# STM32F407ZGT7 register map
File version: 1.0
Registers are 32-bit, access not given, reset 0x0 unless marked. A register's access mark holds for its fields unless they carry their own. Offsets are from the block's base; [hi:lo] are bit positions; {n}, {i} and the like mark numbered series.

## ADC123_COMMON
Base 0x40012300
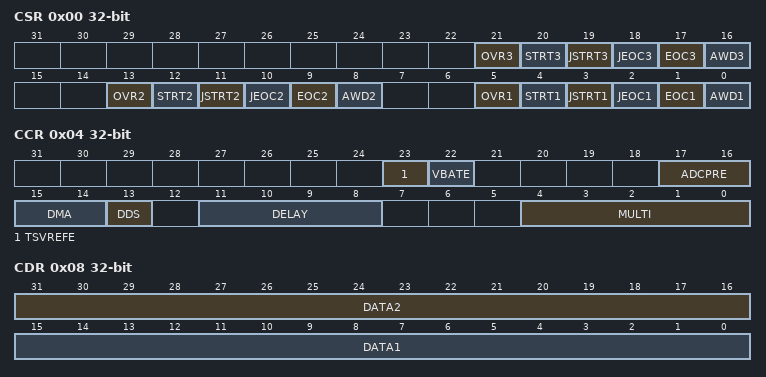
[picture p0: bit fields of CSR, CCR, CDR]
0x00 CSR
  [21] OVR3, [20] STRT3, [19] JSTRT3, [18] JEOC3, [17] EOC3, [16] AWD3, [13] OVR2, [12] STRT2, [11] JSTRT2, [10] JEOC2, [9] EOC2, [8] AWD2, [5] OVR1, [4] STRT1, [3] JSTRT1, [2] JEOC1, [1] EOC1, [0] AWD1
0x04 CCR
  [23] TSVREFE, [22] VBATE, [17:16] ADCPRE, [15:14] DMA, [13] DDS, [11:8] DELAY, [4:0] MULTI
0x08 CDR
  [31:16] DATA2, [15:0] DATA1

## SDIO
Base 0x40012C00
0x00 POWER
  [1:0] PWRCTRL
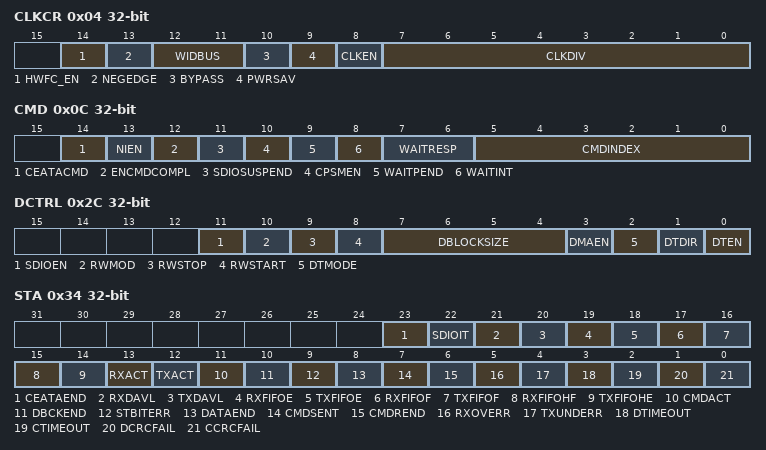
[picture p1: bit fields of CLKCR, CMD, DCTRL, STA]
0x04 CLKCR
  [14] HWFC_EN, [13] NEGEDGE, [12:11] WIDBUS, [10] BYPASS, [9] PWRSAV, [8] CLKEN, [7:0] CLKDIV
0x08 ARG
  [31:0] CMDARG
0x0C CMD
  [14] CEATACMD, [13] NIEN, [12] ENCMDCOMPL, [11] SDIOSUSPEND, [10] CPSMEN, [9] WAITPEND, [8] WAITINT, [7:6] WAITRESP, [5:0] CMDINDEX
0x10 RESPCMD
  [5:0] RESPCMD
{0x10+4i} RESP{i} (i=1..4)
  [31:0] CARDSTATUS{i}
0x24 DTIMER
  [31:0] DATATIME
0x28 DLEN
  [24:0] DATALENGTH
0x2C DCTRL
  [11] SDIOEN, [10] RWMOD, [9] RWSTOP, [8] RWSTART, [7:4] DBLOCKSIZE, [3] DMAEN, [2] DTMODE, [1] DTDIR, [0] DTEN
0x30 DCOUNT
  [24:0] DATACOUNT
0x34 STA
  [23] CEATAEND, [22] SDIOIT, [21] RXDAVL, [20] TXDAVL, [19] RXFIFOE, [18] TXFIFOE, [17] RXFIFOF, [16] TXFIFOF, [15] RXFIFOHF, [14] TXFIFOHE, [13] RXACT, [12] TXACT, [11] CMDACT, [10] DBCKEND, [9] STBITERR, [8] DATAEND, [7] CMDSENT, [6] CMDREND, [5] RXOVERR, [4] TXUNDERR, [3] DTIMEOUT, [2] CTIMEOUT, [1] DCRCFAIL, [0] CCRCFAIL
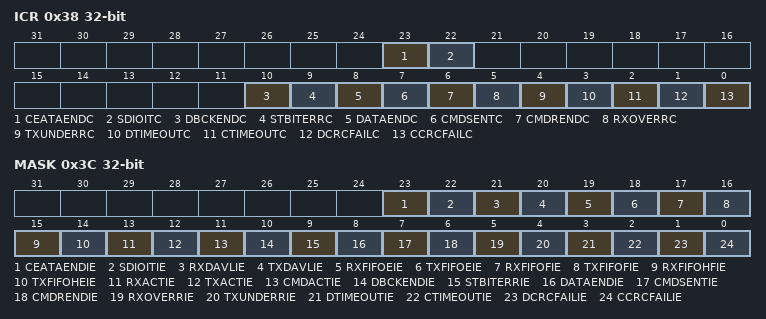
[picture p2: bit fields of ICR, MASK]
0x38 ICR
  [23] CEATAENDC, [22] SDIOITC, [10] DBCKENDC, [9] STBITERRC, [8] DATAENDC, [7] CMDSENTC, [6] CMDRENDC, [5] RXOVERRC, [4] TXUNDERRC, [3] DTIMEOUTC, [2] CTIMEOUTC, [1] DCRCFAILC, [0] CCRCFAILC
0x3C MASK
  [23] CEATAENDIE, [22] SDIOITIE, [21] RXDAVLIE, [20] TXDAVLIE, [19] RXFIFOEIE, [18] TXFIFOEIE, [17] RXFIFOFIE, [16] TXFIFOFIE, [15] RXFIFOHFIE, [14] TXFIFOHEIE, [13] RXACTIE, [12] TXACTIE, [11] CMDACTIE, [10] DBCKENDIE, [9] STBITERRIE, [8] DATAENDIE, [7] CMDSENTIE, [6] CMDRENDIE, [5] RXOVERRIE, [4] TXUNDERRIE, [3] DTIMEOUTIE, [2] CTIMEOUTIE, [1] DCRCFAILIE, [0] CCRCFAILIE
0x48 FIFOCNT
  [23:0] FIFOCOUNT
0x80 FIFO
  [31:0] FIFODATA

## SYSCFG
Base 0x40013800
0x00 MEMRMP
  [1:0] MEM_MODE
0x04 PMC
  [23] MII_RMII_SEL
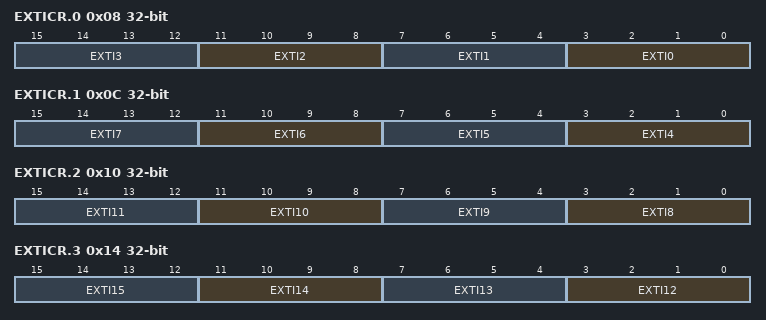
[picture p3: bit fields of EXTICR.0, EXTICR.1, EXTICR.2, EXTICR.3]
0x08 EXTICR.0
  [4n+3:4n] EXTI{n} (n=0..3)
0x0C EXTICR.1
  [4n-13:4n-16] EXTI{n} (n=4..7)
0x10 EXTICR.2
  [4n-29:4n-32] EXTI{n} (n=8..11)
0x14 EXTICR.3
  [4n-45:4n-48] EXTI{n} (n=12..15)
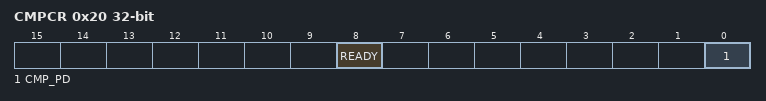
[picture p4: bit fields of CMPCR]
0x20 CMPCR
  [8] READY, [0] CMP_PD

## EXTI
Base 0x40013C00
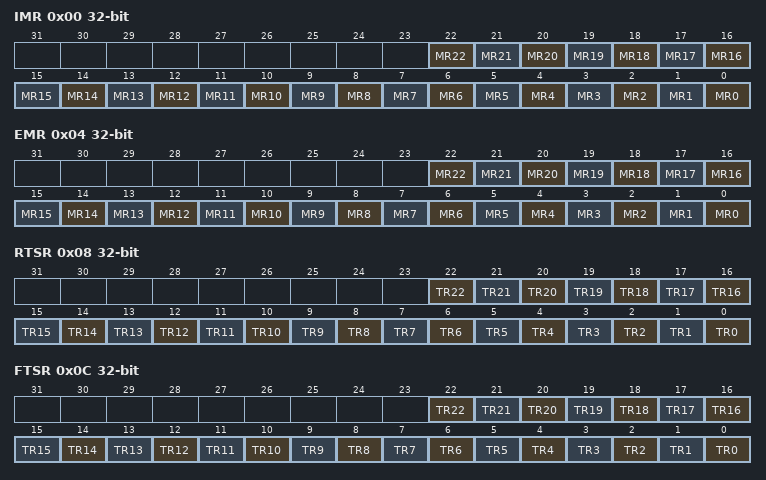
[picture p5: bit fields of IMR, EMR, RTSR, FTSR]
0x00 IMR
  [n] MR{n} (n=0..22)
0x04 EMR
  [n] MR{n} (n=0..22)
0x08 RTSR
  [n] TR{n} (n=0..22)
0x0C FTSR
  [n] TR{n} (n=0..22)
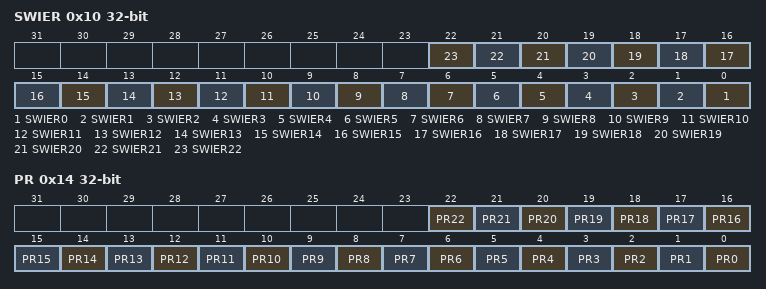
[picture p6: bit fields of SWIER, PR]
0x10 SWIER
  [n] SWIER{n} (n=0..22)
0x14 PR
  [n] PR{n} (n=0..22)

## GPIOA
Base 0x40020000
Same registers: GPIOB 0x40020400, GPIOC 0x40020800, GPIOD 0x40020C00, GPIOE 0x40021000, GPIOF 0x40021400, GPIOG 0x40021800, GPIOH 0x40021C00, GPIOI 0x40022000
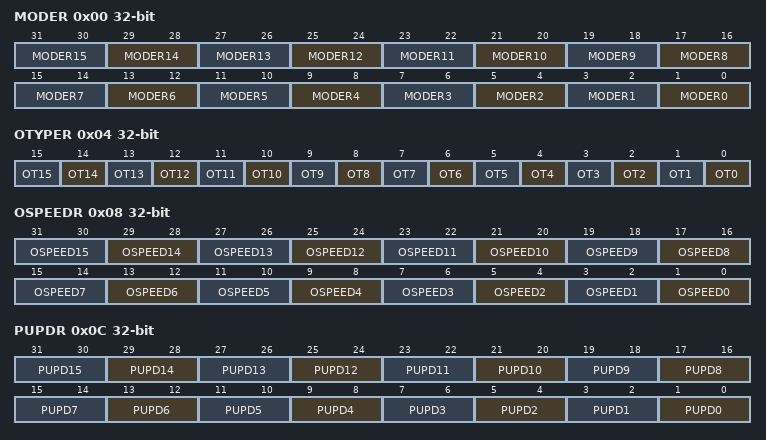
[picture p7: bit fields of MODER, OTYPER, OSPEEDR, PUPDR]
0x00 MODER
  [2n+1:2n] MODER{n} (n=0..15)
0x04 OTYPER
  [n] OT{n} (n=0..15)
0x08 OSPEEDR
  [2n+1:2n] OSPEED{n} (n=0..15)
0x0C PUPDR
  [2n+1:2n] PUPD{n} (n=0..15)
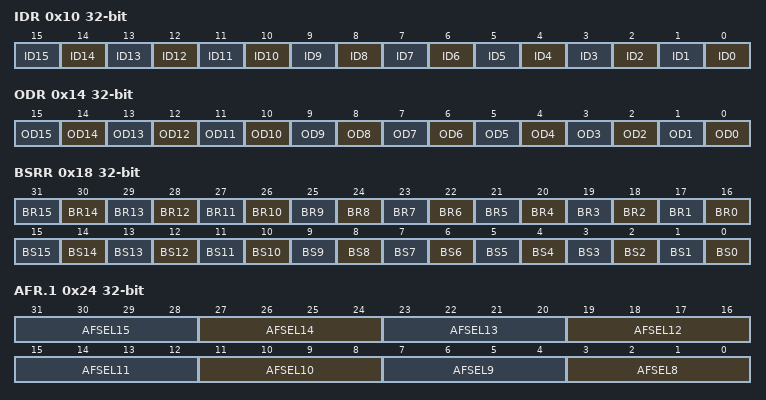
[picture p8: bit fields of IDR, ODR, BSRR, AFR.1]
0x10 IDR
  [n] ID{n} (n=0..15)
0x14 ODR
  [n] OD{n} (n=0..15)
0x18 BSRR
  [n+16] BR{n} (n=0..15), [n] BS{n} (n=0..15)
0x1C LCKR
0x20 AFR.0
0x24 AFR.1
  [4n-29:4n-32] AFSEL{n} (n=8..15)

## CRC
Base 0x40023000
0x00 DR
0x04 IDR 8-bit
0x08 CR
  [0] RESET

## RCC
Base 0x40023800
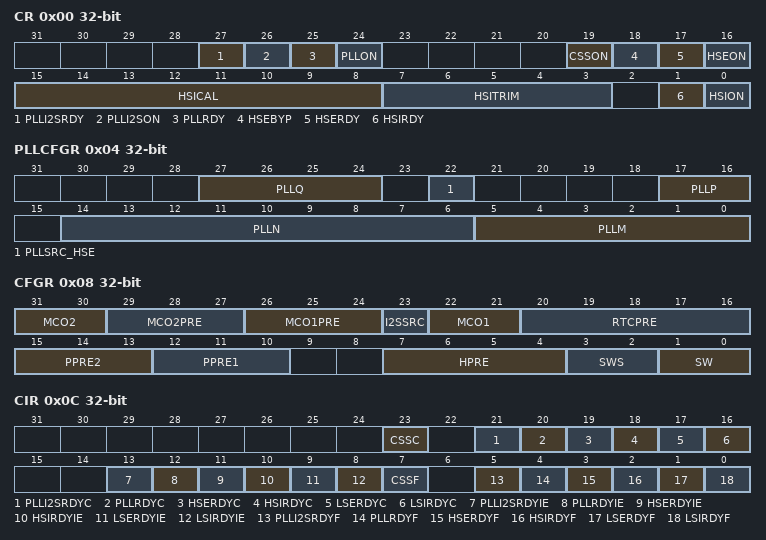
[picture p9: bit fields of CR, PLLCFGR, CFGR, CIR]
0x00 CR
  [27] PLLI2SRDY, [26] PLLI2SON, [25] PLLRDY, [24] PLLON, [19] CSSON, [18] HSEBYP, [17] HSERDY, [16] HSEON, [15:8] HSICAL, [7:3] HSITRIM, [1] HSIRDY, [0] HSION
0x04 PLLCFGR
  [27:24] PLLQ, [22] PLLSRC_HSE, [17:16] PLLP, [14:6] PLLN, [5:0] PLLM
0x08 CFGR
  [31:30] MCO2, [29:27] MCO2PRE, [26:24] MCO1PRE, [23] I2SSRC, [22:21] MCO1, [20:16] RTCPRE, [15:13] PPRE2, [12:10] PPRE1, [7:4] HPRE, [3:2] SWS, [1:0] SW
0x0C CIR
  [23] CSSC, [21] PLLI2SRDYC, [20] PLLRDYC, [19] HSERDYC, [18] HSIRDYC, [17] LSERDYC, [16] LSIRDYC, [13] PLLI2SRDYIE, [12] PLLRDYIE, [11] HSERDYIE, [10] HSIRDYIE, [9] LSERDYIE, [8] LSIRDYIE, [7] CSSF, [5] PLLI2SRDYF, [4] PLLRDYF, [3] HSERDYF, [2] HSIRDYF, [1] LSERDYF, [0] LSIRDYF
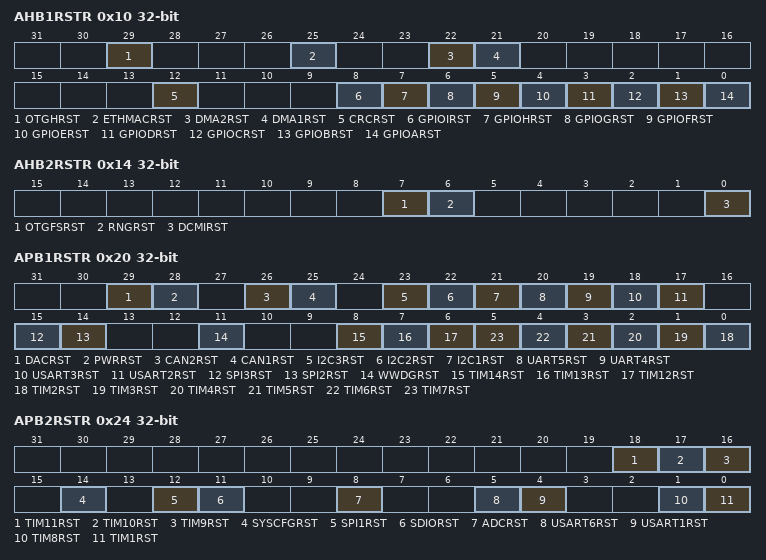
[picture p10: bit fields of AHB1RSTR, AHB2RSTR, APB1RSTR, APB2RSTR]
0x10 AHB1RSTR
  [29] OTGHRST, [25] ETHMACRST, [22] DMA2RST, [21] DMA1RST, [12] CRCRST, [8] GPIOIRST, [7] GPIOHRST, [6] GPIOGRST, [5] GPIOFRST, [4] GPIOERST, [3] GPIODRST, [2] GPIOCRST, [1] GPIOBRST, [0] GPIOARST
0x14 AHB2RSTR
  [7] OTGFSRST, [6] RNGRST, [0] DCMIRST
0x18 AHB3RSTR
  [0] FSMCRST
0x20 APB1RSTR
  [29] DACRST, [28] PWRRST, [26] CAN2RST, [25] CAN1RST, [23] I2C3RST, [22] I2C2RST, [21] I2C1RST, [20] UART5RST, [19] UART4RST, [18] USART3RST, [17] USART2RST, [15] SPI3RST, [14] SPI2RST, [11] WWDGRST, [8] TIM14RST, [7] TIM13RST, [6] TIM12RST, [n-2] TIM{n}RST (n=2..7)
0x24 APB2RSTR
  [18] TIM11RST, [17] TIM10RST, [16] TIM9RST, [14] SYSCFGRST, [12] SPI1RST, [11] SDIORST, [8] ADCRST, [5] USART6RST, [4] USART1RST, [1] TIM8RST, [0] TIM1RST
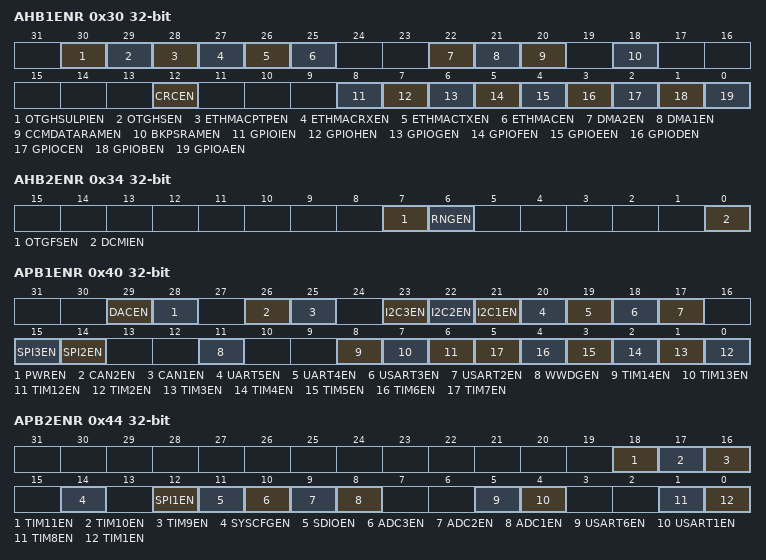
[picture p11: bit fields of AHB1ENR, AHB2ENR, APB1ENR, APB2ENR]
0x30 AHB1ENR
  [30] OTGHSULPIEN, [29] OTGHSEN, [28] ETHMACPTPEN, [27] ETHMACRXEN, [26] ETHMACTXEN, [25] ETHMACEN, [22] DMA2EN, [21] DMA1EN, [20] CCMDATARAMEN, [18] BKPSRAMEN, [12] CRCEN, [8] GPIOIEN, [7] GPIOHEN, [6] GPIOGEN, [5] GPIOFEN, [4] GPIOEEN, [3] GPIODEN, [2] GPIOCEN, [1] GPIOBEN, [0] GPIOAEN
0x34 AHB2ENR
  [7] OTGFSEN, [6] RNGEN, [0] DCMIEN
0x38 AHB3ENR
  [0] FSMCEN
0x40 APB1ENR
  [29] DACEN, [28] PWREN, [26] CAN2EN, [25] CAN1EN, [23] I2C3EN, [22] I2C2EN, [21] I2C1EN, [20] UART5EN, [19] UART4EN, [18] USART3EN, [17] USART2EN, [15] SPI3EN, [14] SPI2EN, [11] WWDGEN, [8] TIM14EN, [7] TIM13EN, [6] TIM12EN, [n-2] TIM{n}EN (n=2..7)
0x44 APB2ENR
  [18] TIM11EN, [17] TIM10EN, [16] TIM9EN, [14] SYSCFGEN, [12] SPI1EN, [11] SDIOEN, [10] ADC3EN, [9] ADC2EN, [8] ADC1EN, [5] USART6EN, [4] USART1EN, [1] TIM8EN, [0] TIM1EN
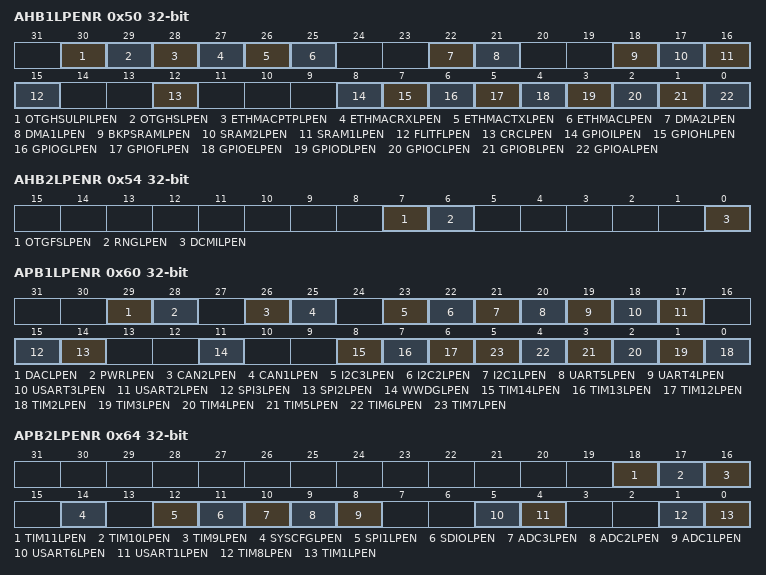
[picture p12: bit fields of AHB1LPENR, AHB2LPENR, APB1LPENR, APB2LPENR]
0x50 AHB1LPENR
  [30] OTGHSULPILPEN, [29] OTGHSLPEN, [28] ETHMACPTPLPEN, [27] ETHMACRXLPEN, [26] ETHMACTXLPEN, [25] ETHMACLPEN, [22] DMA2LPEN, [21] DMA1LPEN, [18] BKPSRAMLPEN, [17] SRAM2LPEN, [16] SRAM1LPEN, [15] FLITFLPEN, [12] CRCLPEN, [8] GPIOILPEN, [7] GPIOHLPEN, [6] GPIOGLPEN, [5] GPIOFLPEN, [4] GPIOELPEN, [3] GPIODLPEN, [2] GPIOCLPEN, [1] GPIOBLPEN, [0] GPIOALPEN
0x54 AHB2LPENR
  [7] OTGFSLPEN, [6] RNGLPEN, [0] DCMILPEN
0x58 AHB3LPENR
  [0] FSMCLPEN
0x60 APB1LPENR
  [29] DACLPEN, [28] PWRLPEN, [26] CAN2LPEN, [25] CAN1LPEN, [23] I2C3LPEN, [22] I2C2LPEN, [21] I2C1LPEN, [20] UART5LPEN, [19] UART4LPEN, [18] USART3LPEN, [17] USART2LPEN, [15] SPI3LPEN, [14] SPI2LPEN, [11] WWDGLPEN, [8] TIM14LPEN, [7] TIM13LPEN, [6] TIM12LPEN, [n-2] TIM{n}LPEN (n=2..7)
0x64 APB2LPENR
  [18] TIM11LPEN, [17] TIM10LPEN, [16] TIM9LPEN, [14] SYSCFGLPEN, [12] SPI1LPEN, [11] SDIOLPEN, [10] ADC3LPEN, [9] ADC2LPEN, [8] ADC1LPEN, [5] USART6LPEN, [4] USART1LPEN, [1] TIM8LPEN, [0] TIM1LPEN
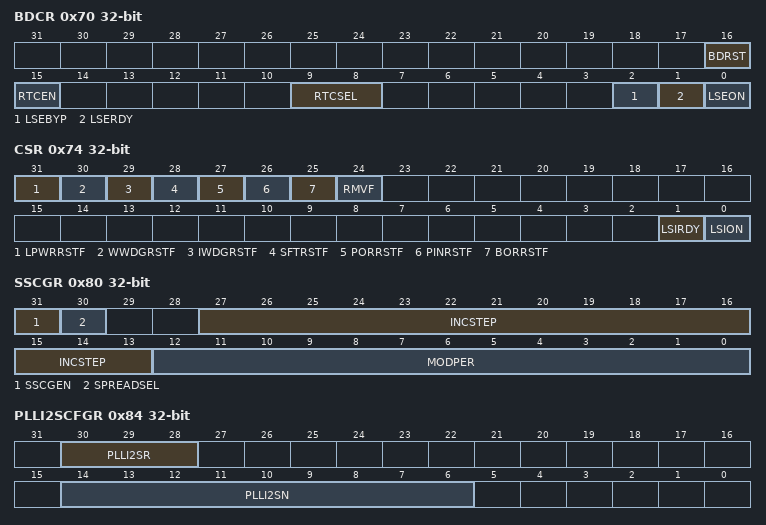
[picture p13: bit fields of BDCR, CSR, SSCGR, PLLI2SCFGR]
0x70 BDCR
  [16] BDRST, [15] RTCEN, [9:8] RTCSEL, [2] LSEBYP, [1] LSERDY, [0] LSEON
0x74 CSR
  [31] LPWRRSTF, [30] WWDGRSTF, [29] IWDGRSTF, [28] SFTRSTF, [27] PORRSTF, [26] PINRSTF, [25] BORRSTF, [24] RMVF, [1] LSIRDY, [0] LSION
0x80 SSCGR
  [31] SSCGEN, [30] SPREADSEL, [27:13] INCSTEP, [12:0] MODPER
0x84 PLLI2SCFGR
  [30:28] PLLI2SR, [14:6] PLLI2SN
